# Example register map
Vendor: Google Inc.; File version: 0.1.0
Example of a package
Registers are 8-bit, read-write, reset 0x0 unless marked. A register's access mark holds for its fields unless they carry their own. Offsets are from the block's base; lines under a group give offsets from that group; [hi:lo] are bit positions; {n}, {i} and the like mark numbered series; 'fields as' and 'values as' point back to an identical list; <NAME> marks a mode.

## Memory map
0x00000010 Example size 0xFF — Example of a package

## Example — Example of a package
Base 0x00000010
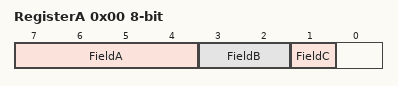
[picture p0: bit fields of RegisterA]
0x00 RegisterA — An 8-bit register
  [7:4] FieldA ro range 4..7 — This is a few bits
  [3:2] FieldB wo range 2..3 — This is fewer bits
    1=Value 1; 2=Value 2; 4=Value 3; 8=Value 4
  [1] FieldC range 1..1 — A single-bit
0x01 RegisterB 16-bit (reset mask 0xFF) — A 16-bit register
0x02 RegisterC 32-bit (reset mask 0xFF) — A 32-bit register
0x03 RegisterD size not given — A dummy register that has no data

## Licence text in the file
Copyright (C) 2019 Google Inc. Licensed under the Apache License, Version 2.0 (the "License"); you may not use this file except in compliance with the License. You may obtain a copy of the License at http://www.apache.org/licenses/LICENSE-2.0 Unless required by applicable law or agreed to in writing, software distributed under the License is distributed on an "AS IS" BASIS, WITHOUT WARRANTIES OR CONDITIONS OF ANY KIND, either express or implied. See the License for the specific language governing permissions and limitations under the License.
